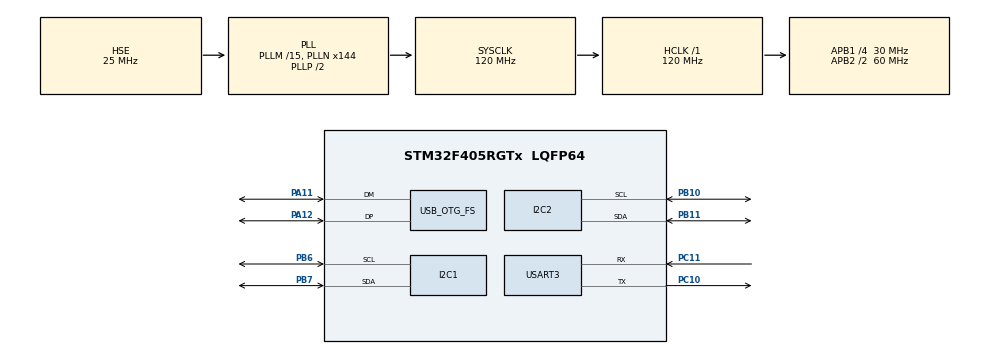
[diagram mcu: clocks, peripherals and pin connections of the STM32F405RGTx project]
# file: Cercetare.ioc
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Mcu.Family=STM32F4
Mcu.Name=STM32F405RGTx
Mcu.Package=LQFP64
NVIC.OTG_FS_IRQn=true\:0\:0\:false\:false\:true\:false\:true\:true
NVIC.PriorityGroup=NVIC_PRIORITYGROUP_4
PA11.Mode=Device_Only
PA11.Signal=USB_OTG_FS_DM
PA12.Mode=Device_Only
PA12.Signal=USB_OTG_FS_DP
PA13.Mode=JTAG_4_pins
PA13.Signal=SYS_JTMS-SWDIO
PA14.Mode=JTAG_4_pins
PA14.Signal=SYS_JTCK-SWCLK
PA15.Mode=JTAG_4_pins
PA15.Signal=SYS_JTDI
PB10.Mode=I2C
PB10.Signal=I2C2_SCL
PB11.Mode=I2C
PB11.Signal=I2C2_SDA
PB3.Mode=JTAG_4_pins
PB3.Signal=SYS_JTDO-SWO
PB6.Mode=I2C
PB6.Signal=I2C1_SCL
PB7.Mode=I2C
PB7.Signal=I2C1_SDA
PC10.Mode=Asynchronous
PC10.Signal=USART3_TX
PC11.Mode=Asynchronous
PC11.Signal=USART3_RX
PH0-OSC_IN.Mode=HSE-External-Oscillator
PH0-OSC_IN.Signal=RCC_OSC_IN
PH1-OSC_OUT.Mode=HSE-External-Oscillator
PH1-OSC_OUT.Signal=RCC_OSC_OUT
ProjectManager.HeapSize=0x200
ProjectManager.StackSize=0x400
ProjectManager.TargetToolchain=STM32CubeIDE
RCC.48MHZClocksFreq_Value=48000000
RCC.AHBFreq_Value=120000000
RCC.APB1CLKDivider=RCC_HCLK_DIV4
RCC.APB1Freq_Value=30000000
RCC.APB1TimFreq_Value=60000000
RCC.APB2CLKDivider=RCC_HCLK_DIV2
RCC.APB2Freq_Value=60000000
RCC.APB2TimFreq_Value=120000000
RCC.CortexFreq_Value=120000000
RCC.HCLKFreq_Value=120000000
RCC.HSE_VALUE=25000000
RCC.HSI_VALUE=16000000
RCC.LSE_VALUE=32768
RCC.PLLM=15
RCC.PLLN=144
RCC.PLLQ=5
RCC.SYSCLKFreq_VALUE=120000000
RCC.SYSCLKSource=RCC_SYSCLKSOURCE_PLLCLK
RCC.VCOOutputFreq_Value=240000000
USART3.VirtualMode=VM_ASYNC
USB_DEVICE.CLASS_NAME_FS=CDC
USB_DEVICE.VirtualMode-CDC_FS=Cdc
USB_DEVICE.VirtualModeFS=Cdc_FS
USB_OTG_FS.VirtualMode=Device_Only
VP_USB_DEVICE_VS_USB_DEVICE_CDC_FS.Mode=CDC_FS
board=custom

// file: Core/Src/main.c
/* USER CODE BEGIN Header */
/**
  ******************************************************************************
  * @file           : main.c
  * @brief          : Main program body
  ******************************************************************************
  * @attention
  *
  * Copyright (c) 2024 STMicroelectronics.
  * All rights reserved.
  *
  * This software is licensed under terms that can be found in the LICENSE file
  * in the root directory of this software component.
  * If no LICENSE file comes with this software, it is provided AS-IS.
  *
  ******************************************************************************
  */
/* USER CODE END Header */
#include "main.h"
#include "usb_device.h"

/* USER CODE BEGIN Includes */
#include "INA219.h"
/* USER CODE END Includes */

I2C_HandleTypeDef hi2c1;
I2C_HandleTypeDef hi2c2;

UART_HandleTypeDef huart3;

/* USER CODE BEGIN PV */
INA219_t ina219;

uint16_t vbus, vshunt, current;
/* USER CODE END PV */

void SystemClock_Config(void);
static void MX_GPIO_Init(void);
static void MX_I2C1_Init(void);
static void MX_USART3_UART_Init(void);
static void MX_I2C2_Init(void);

int main(void)
{

  /* MCU Configuration--------------------------------------------------------*/

  /* Reset of all peripherals, Initializes the Flash interface and the Systick. */
  HAL_Init();

  /* Configure the system clock */
  SystemClock_Config();

  /* Initialize all configured peripherals */
  MX_GPIO_Init();
  MX_I2C1_Init();
  MX_USART3_UART_Init();
  MX_I2C2_Init();
  MX_USB_DEVICE_Init();
  /* USER CODE BEGIN 2 */
  while(!INA219_Init(&ina219, &hi2c1, INA219_ADDRESS))
  {

  }
/* USER CODE END 2 */

  /* Infinite loop */
  while (1)
  {
	  vbus = INA219_ReadBusVoltage(&ina219);
	      vshunt = INA219_ReadShuntVolage(&ina219);
	      current = INA219_ReadCurrent(&ina219);

	      char vbus_str[10], vshunt_str[10], current_str[10];
	      sprintf(vbus_str, "%u", vbus);
	      sprintf(vshunt_str, "%u", vshunt);
	      sprintf(current_str, "%u", current);

	      char data_str[50];
	      sprintf(data_str, "Voltage: %s mV, Shunt Voltage: %s mV, Current: %s mA\r\n", vbus_str, vshunt_str, current_str);

	      /
	      HAL_UART_Transmit(&huart3, (uint8_t *)data_str, strlen(data_str), HAL_MAX_DELAY);

	      HAL_Delay(1000);
  }
}

void SystemClock_Config(void)
{
  RCC_OscInitTypeDef RCC_OscInitStruct = {0};
  RCC_ClkInitTypeDef RCC_ClkInitStruct = {0};

  /** Configure the main internal regulator output voltage
  */
  __HAL_RCC_PWR_CLK_ENABLE();
  __HAL_PWR_VOLTAGESCALING_CONFIG(PWR_REGULATOR_VOLTAGE_SCALE1);

  /** Initializes the RCC Oscillators according to the specified parameters
  * in the RCC_OscInitTypeDef structure.
  */
  RCC_OscInitStruct.OscillatorType = RCC_OSCILLATORTYPE_HSE;
  RCC_OscInitStruct.HSEState = RCC_HSE_ON;
  RCC_OscInitStruct.PLL.PLLState = RCC_PLL_ON;
  RCC_OscInitStruct.PLL.PLLSource = RCC_PLLSOURCE_HSE;
  RCC_OscInitStruct.PLL.PLLM = 15;
  RCC_OscInitStruct.PLL.PLLN = 144;
  RCC_OscInitStruct.PLL.PLLP = RCC_PLLP_DIV2;
  RCC_OscInitStruct.PLL.PLLQ = 5;
  if (HAL_RCC_OscConfig(&RCC_OscInitStruct) != HAL_OK)
  {
    Error_Handler();
  }

  /** Initializes the CPU, AHB and APB buses clocks
  */
  RCC_ClkInitStruct.ClockType = RCC_CLOCKTYPE_HCLK|RCC_CLOCKTYPE_SYSCLK
                              |RCC_CLOCKTYPE_PCLK1|RCC_CLOCKTYPE_PCLK2;
  RCC_ClkInitStruct.SYSCLKSource = RCC_SYSCLKSOURCE_PLLCLK;
  RCC_ClkInitStruct.AHBCLKDivider = RCC_SYSCLK_DIV1;
  RCC_ClkInitStruct.APB1CLKDivider = RCC_HCLK_DIV4;
  RCC_ClkInitStruct.APB2CLKDivider = RCC_HCLK_DIV2;

  if (HAL_RCC_ClockConfig(&RCC_ClkInitStruct, FLASH_LATENCY_3) != HAL_OK)
  {
    Error_Handler();
  }
}

static void MX_I2C1_Init(void)
{

  hi2c1.Instance = I2C1;
  hi2c1.Init.ClockSpeed = 100000;
  hi2c1.Init.DutyCycle = I2C_DUTYCYCLE_2;
  hi2c1.Init.OwnAddress1 = 0;
  hi2c1.Init.AddressingMode = I2C_ADDRESSINGMODE_7BIT;
  hi2c1.Init.DualAddressMode = I2C_DUALADDRESS_DISABLE;
  hi2c1.Init.OwnAddress2 = 0;
  hi2c1.Init.GeneralCallMode = I2C_GENERALCALL_DISABLE;
  hi2c1.Init.NoStretchMode = I2C_NOSTRETCH_DISABLE;
  if (HAL_I2C_Init(&hi2c1) != HAL_OK)
  {
    Error_Handler();
  }

}

static void MX_I2C2_Init(void)
{

  hi2c2.Instance = I2C2;
  hi2c2.Init.ClockSpeed = 100000;
  hi2c2.Init.DutyCycle = I2C_DUTYCYCLE_2;
  hi2c2.Init.OwnAddress1 = 0;
  hi2c2.Init.AddressingMode = I2C_ADDRESSINGMODE_7BIT;
  hi2c2.Init.DualAddressMode = I2C_DUALADDRESS_DISABLE;
  hi2c2.Init.OwnAddress2 = 0;
  hi2c2.Init.GeneralCallMode = I2C_GENERALCALL_DISABLE;
  hi2c2.Init.NoStretchMode = I2C_NOSTRETCH_DISABLE;
  if (HAL_I2C_Init(&hi2c2) != HAL_OK)
  {
    Error_Handler();
  }

}

static void MX_USART3_UART_Init(void)
{

  huart3.Instance = USART3;
  huart3.Init.BaudRate = 115200;
  huart3.Init.WordLength = UART_WORDLENGTH_8B;
  huart3.Init.StopBits = UART_STOPBITS_1;
  huart3.Init.Parity = UART_PARITY_NONE;
  huart3.Init.Mode = UART_MODE_TX_RX;
  huart3.Init.HwFlowCtl = UART_HWCONTROL_NONE;
  huart3.Init.OverSampling = UART_OVERSAMPLING_16;
  if (HAL_UART_Init(&huart3) != HAL_OK)
  {
    Error_Handler();
  }

}

static void MX_GPIO_Init(void)
{

  /* GPIO Ports Clock Enable */
  __HAL_RCC_GPIOH_CLK_ENABLE();
  __HAL_RCC_GPIOB_CLK_ENABLE();
  __HAL_RCC_GPIOA_CLK_ENABLE();
  __HAL_RCC_GPIOC_CLK_ENABLE();

}

void Error_Handler(void)
{
  __disable_irq();
  while (1)
  {
  }
}
